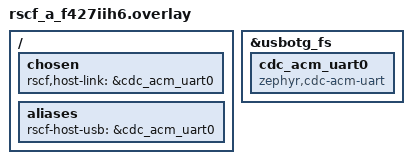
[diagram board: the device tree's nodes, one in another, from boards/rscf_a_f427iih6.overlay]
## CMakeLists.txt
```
cmake_minimum_required(VERSION 3.20.0)

list(APPEND BOARD_ROOT ${CMAKE_CURRENT_LIST_DIR}/..)
list(APPEND DTS_ROOT ${CMAKE_CURRENT_LIST_DIR}/..)
set(RSCF_SEGGER_MODULE_DIR ${CMAKE_CURRENT_LIST_DIR}/../modules/debug/segger)
set(RSCF_MICROROS_MODULE_DIR ${CMAKE_CURRENT_LIST_DIR}/../modules/lib/libmicroros)

if(EXISTS ${RSCF_SEGGER_MODULE_DIR}/zephyr/module.yml)
  list(APPEND ZEPHYR_EXTRA_MODULES ${RSCF_SEGGER_MODULE_DIR})
endif()

if(EXISTS ${RSCF_MICROROS_MODULE_DIR}/zephyr/module.yml)
  list(APPEND ZEPHYR_EXTRA_MODULES ${RSCF_MICROROS_MODULE_DIR})
endif()

find_package(Zephyr REQUIRED HINTS $ENV{ZEPHYR_BASE})
find_package(Python3 REQUIRED COMPONENTS Interpreter)
project(rscf_a_zephyr)
get_filename_component(RSCF_WEST_TOPDIR ${ZEPHYR_BASE} DIRECTORY)

set(RSCF_CMSIS_DSP_DIR ${CMAKE_CURRENT_LIST_DIR}/../third_party/cmsis_dsp)
set(RSCF_CMSIS_DSP_INCLUDE_DIR ${CMAKE_CURRENT_LIST_DIR}/../third_party/cmsis_dsp/Include)
set(RSCF_CMSIS_DSP_PRIVATE_INCLUDE_DIR ${CMAKE_CURRENT_LIST_DIR}/../third_party/cmsis_dsp/PrivateInclude)

set(RSCF_MCU_DEVICE "MCU_ONE" CACHE STRING "mcu_comm target MCU device")
set(RSCF_MCU_COMM_OUTPUT_DIR ${CMAKE_BINARY_DIR}/generated/mcu_comm/${RSCF_MCU_DEVICE})
set(RSCF_MCU_COMM_APP_DIR ${RSCF_MCU_COMM_OUTPUT_DIR}/app)
set(RSCF_MCU_COMM_CORE_DIR ${RSCF_MCU_COMM_OUTPUT_DIR}/core)
set(RSCF_MCU_COMM_TRANSPORT_DIR ${RSCF_MCU_COMM_OUTPUT_DIR}/transports)
set(RSCF_MCU_COMM_SYNC_DIR ${CMAKE_CURRENT_LIST_DIR}/../generated/mcu_comm)
file(GLOB RSCF_MCU_COMM_ZEPHYR_TEMPLATES
  ${CMAKE_CURRENT_LIST_DIR}/../mcu_comm/protocol_generator/templates/zephyr/*.j2
)

set(RSCF_MCU_COMM_GENERATED_HEADERS
  ${RSCF_MCU_COMM_APP_DIR}/data_def.h
  ${RSCF_MCU_COMM_APP_DIR}/robot_interface.h
  ${RSCF_MCU_COMM_CORE_DIR}/protocol.h
  ${RSCF_MCU_COMM_CORE_DIR}/comm_manager.h
  ${RSCF_MCU_COMM_TRANSPORT_DIR}/transport_interface.h
  ${RSCF_MCU_COMM_TRANSPORT_DIR}/transport_uart.h
  ${RSCF_MCU_COMM_TRANSPORT_DIR}/transport_can.h
  ${RSCF_MCU_COMM_TRANSPORT_DIR}/transport_usb.h
)

set(RSCF_MCU_COMM_GENERATED_SOURCES
  ${RSCF_MCU_COMM_APP_DIR}/data_def.c
  ${RSCF_MCU_COMM_APP_DIR}/robot_interface.c
  ${RSCF_MCU_COMM_CORE_DIR}/protocol.c
  ${RSCF_MCU_COMM_CORE_DIR}/comm_manager.c
  ${RSCF_MCU_COMM_TRANSPORT_DIR}/transport_uart.c
  ${RSCF_MCU_COMM_TRANSPORT_DIR}/transport_can.c
  ${RSCF_MCU_COMM_TRANSPORT_DIR}/transport_usb.c
)

add_custom_command(
  OUTPUT ${RSCF_MCU_COMM_GENERATED_HEADERS} ${RSCF_MCU_COMM_GENERATED_SOURCES}
  COMMAND ${Python3_EXECUTABLE}
          ${CMAKE_CURRENT_LIST_DIR}/../scripts/codegen/rscf_mcu_comm_codegen.py
          --device ${RSCF_MCU_DEVICE}
          --output-dir ${RSCF_MCU_COMM_OUTPUT_DIR}
  DEPENDS
          ${CMAKE_CURRENT_LIST_DIR}/../scripts/codegen/rscf_mcu_comm_codegen.py
          ${CMAKE_CURRENT_LIST_DIR}/../mcu_comm/protocol_generator/generator.py
          ${CMAKE_CURRENT_LIST_DIR}/../mcu_comm/protocol_generator/protocol_definition.json
          ${CMAKE_CURRENT_LIST_DIR}/../mcu_comm/protocol_generator/system_status_schema.yaml
          ${CMAKE_CURRENT_LIST_DIR}/../mcu_comm/protocol_generator/system_cmd_schema.yaml
          ${CMAKE_CURRENT_LIST_DIR}/../mcu_comm/protocol_generator/control_plane_enums.yaml
          ${RSCF_MCU_COMM_ZEPHYR_TEMPLATES}
  VERBATIM
)

add_custom_target(rscf_mcu_comm_codegen DEPENDS
  ${RSCF_MCU_COMM_GENERATED_HEADERS}
  ${RSCF_MCU_COMM_GENERATED_SOURCES}
)

add_custom_target(rscf_mcu_comm_sync
  COMMAND ${Python3_EXECUTABLE}
          ${CMAKE_CURRENT_LIST_DIR}/../scripts/codegen/rscf_mcu_comm_codegen.py
          --device ${RSCF_MCU_DEVICE}
          --output-dir ${RSCF_MCU_COMM_OUTPUT_DIR}
          --sync-dir ${RSCF_MCU_COMM_SYNC_DIR}
          --sync
  DEPENDS rscf_mcu_comm_codegen
  VERBATIM
)

add_custom_target(rscf_ioc_validate
  COMMAND ${Python3_EXECUTABLE}
          ${CMAKE_CURRENT_LIST_DIR}/../scripts/ioc/validate_board_from_ioc.py
          --repo-root ${CMAKE_CURRENT_LIST_DIR}/..
  VERBATIM
)

zephyr_include_directories(${ZEPHYR_BASE}/modules/cmsis_6)
zephyr_include_directories(${RSCF_WEST_TOPDIR}/third_party/hal/cmsis/CMSIS/Core/Include)
zephyr_compile_definitions(SHPR=SHP)
target_compile_definitions(app PRIVATE ARM_MATH_CM4 ARM_MATH_MATRIX_CHECK ARM_MATH_ROUNDING)

target_include_directories(app PRIVATE
  ${RSCF_CMSIS_DSP_INCLUDE_DIR}
  ${RSCF_CMSIS_DSP_PRIVATE_INCLUDE_DIR}
  ${CMAKE_CURRENT_LIST_DIR}/../include
  ${CMAKE_CURRENT_LIST_DIR}/../drivers/rscf
  ${CMAKE_CURRENT_LIST_DIR}/../drivers/bsp
  ${CMAKE_CURRENT_LIST_DIR}/../modules/rscf/services
  ${CMAKE_CURRENT_LIST_DIR}/../modules/rscf/devices
  ${RSCF_MCU_COMM_APP_DIR}
  ${RSCF_MCU_COMM_CORE_DIR}
  ${RSCF_MCU_COMM_TRANSPORT_DIR}
)

target_sources(app PRIVATE
  src/main.c
  ../drivers/bsp/bsp_usart.c
  ../drivers/bsp/bsp_log.c
  ../drivers/bsp/bsp_dwt.c
  ../drivers/bsp/bsp_can.c
  ../drivers/bsp/bsp_spi.c
  ../drivers/bsp/bsp_pwm.c
  ../drivers/bsp/bsp_tim.c
  ../drivers/rscf/rscf_boot.c
  ../drivers/rscf/rscf_led_status.c
  ../drivers/rscf/rscf_link_usb.c
  ../drivers/rscf/rscf_link_uart.c
  ../drivers/rscf/rscf_link_can.c
  ../drivers/rscf/rscf_link_spi.c
  ../drivers/rscf/rscf_ext_uart_mux.c
  ../drivers/rscf/rscf_buzzer.c
  ../drivers/rscf/rscf_power_switch.c
  ../modules/algorithm/coordinate_system.c
  ../modules/algorithm/crc8.c
  ../modules/algorithm/crc16.c
  ../modules/algorithm/linear_algebra.c
  ../modules/algorithm/Kalman_filter.c
  ../modules/algorithm/PID.c
  ../modules/algorithm/user_lib.c
  ../modules/compat/unit_convert.c
  ../modules/compat/controller.c
  ../modules/compat/daemon.c
  ../modules/compat/led.c
  ../modules/compat/buzzer.c
  ../modules/compat/hc05.c
  ../modules/compat/seasky_protocol.c
  ../modules/compat/master_process.c
  ../modules/compat/mhall.c
  ../modules/compat/ad7190.c
  ../modules/compat/oled.c
  ../modules/compat/remote_control.c
  ../modules/compat/robot.c
  ../modules/compat/robot_cmd.c
  ../modules/compat/motor_task.c
  ../third_party/cmsis_dsp/Source/CommonTables/arm_common_tables.c
  ../third_party/cmsis_dsp/Source/FastMathFunctions/arm_sin_f32.c
  ../third_party/cmsis_dsp/Source/FastMathFunctions/arm_cos_f32.c
  ../third_party/cmsis_dsp/Source/FastMathFunctions/arm_atan2_f32.c
  ../third_party/cmsis_dsp/Source/MatrixFunctions/arm_mat_init_f32.c
  ../third_party/cmsis_dsp/Source/MatrixFunctions/arm_mat_add_f32.c
  ../third_party/cmsis_dsp/Source/MatrixFunctions/arm_mat_sub_f32.c
  ../third_party/cmsis_dsp/Source/MatrixFunctions/arm_mat_mult_f32.c
  ../third_party/cmsis_dsp/Source/MatrixFunctions/arm_mat_trans_f32.c
  ../third_party/cmsis_dsp/Source/MatrixFunctions/arm_mat_inverse_f32.c
  ../modules/motor/dji_motor.c
  ../modules/motor/dmmotor.c
  ../modules/motor/servo_motor.c
  ../modules/rscf/core/rscf_app_profile.c
  ../modules/rscf/services/rscf_event_bus.c
  ../modules/rscf/services/rscf_link_service.c
  ../modules/rscf/services/rscf_service_router.c
  ../modules/rscf/services/rscf_action_service.c
  ../modules/rscf/services/rscf_daemon_service.c
  ../modules/rscf/services/rscf_health_service.c
  ../modules/rscf/services/rscf_comm_service.c
  ../modules/rscf/services/rscf_chassis_service.c
  ../modules/rscf/services/rscf_robot_service.c
  ../modules/rscf/services/rscf_ros_bridge.c
  ../modules/rscf/services/rscf_motor_service.c
  ../modules/rscf/services/rscf_debug_fault.c
  ../modules/rscf/devices/rscf_dtof2510.c
  ../modules/rscf/devices/rscf_imu_uart.c
  ../modules/rscf/devices/rscf_saber_imu_compat.c
  ${RSCF_MCU_COMM_GENERATED_SOURCES}
)

add_dependencies(app rscf_mcu_comm_codegen)
add_dependencies(app rscf_ioc_validate)

if(CONFIG_RSCF_MICROROS_SERVICE)
  target_sources(app PRIVATE
    ../modules/rscf/services/rscf_microros_service.c
  )
endif()
```

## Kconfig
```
mainmenu "RSCF A Zephyr Configuration"

source "Kconfig.zephyr"

menu "RSCF A Options"

rsource "../profiles/Kconfig"
rsource "../modules/rscf/Kconfig"

endmenu
```

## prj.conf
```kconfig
CONFIG_GPIO=y
CONFIG_SERIAL=y
CONFIG_CONSOLE=y
CONFIG_UART_CONSOLE=y
CONFIG_UART_INTERRUPT_DRIVEN=y
CONFIG_UART_LINE_CTRL=y
CONFIG_PINCTRL=y
CONFIG_LOG=y
CONFIG_LOG_MODE_IMMEDIATE=y
CONFIG_LOG_BACKEND_UART=n
CONFIG_LOG_BACKEND_RTT=y
CONFIG_LOG_BACKEND_RTT_MODE_DROP=y
CONFIG_LOG_BACKEND_RTT_MESSAGE_SIZE=256
CONFIG_USE_SEGGER_RTT=y
CONFIG_SEGGER_RTT_MAX_NUM_UP_BUFFERS=5
CONFIG_SEGGER_RTT_MAX_NUM_DOWN_BUFFERS=2
CONFIG_SEGGER_RTT_BUFFER_SIZE_UP=1024
CONFIG_SEGGER_RTT_BUFFER_SIZE_DOWN=64
CONFIG_RING_BUFFER=y
CONFIG_HEAP_MEM_POOL_SIZE=32768
CONFIG_MAIN_STACK_SIZE=24576
CONFIG_REBOOT=y
CONFIG_CAN=y
CONFIG_SPI=y
CONFIG_I2C=n
CONFIG_PWM=y
CONFIG_SENSOR=y
CONFIG_ASSERT=y
CONFIG_CPP=y
CONFIG_NEWLIB_LIBC=y
CONFIG_NEWLIB_LIBC_NANO=n
CONFIG_POSIX_API=y
CONFIG_USB_DEVICE_STACK=y
CONFIG_USB_DEVICE_STACK_NEXT=n
CONFIG_USB_CDC_ACM=y
CONFIG_USB_DEVICE_INITIALIZE_AT_BOOT=n
CONFIG_USB_DEVICE_PRODUCT="RSCF A CDC ACM"
CONFIG_USB_DEVICE_PID=0x2026

CONFIG_RSCF_PROFILE_MINIMAL_BRINGUP=y
CONFIG_RSCF_EVENT_BUS=y
CONFIG_RSCF_DAEMON_SERVICE=y
CONFIG_RSCF_HEALTH_SERVICE=y
CONFIG_RSCF_LINK_VNEXT=y
CONFIG_RSCF_LINK_HOST_USB=y
CONFIG_RSCF_LINK_PEER_UART=y
CONFIG_RSCF_LINK_COMPAT_SYSTEM_CMD=y
CONFIG_RSCF_ROS_BACKEND_BRIDGE=y
CONFIG_RSCF_ROS_BACKEND_MICROROS=n
CONFIG_RSCF_COMM_SERVICE=y
CONFIG_RSCF_CHASSIS_SERVICE=y
CONFIG_RSCF_MOTOR_SERVICE=y
```

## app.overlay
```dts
&usbotg_fs {
	cdc_acm_uart0: cdc_acm_uart0 {
		compatible = "zephyr,cdc-acm-uart";
	};
};
```

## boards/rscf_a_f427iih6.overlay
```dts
/ {
	chosen {
		rscf,host-link = &cdc_acm_uart0;
	};

	aliases {
		rscf-host-usb = &cdc_acm_uart0;
	};
};

&usbotg_fs {
	cdc_acm_uart0: cdc_acm_uart0 {
		compatible = "zephyr,cdc-acm-uart";
	};
};
```

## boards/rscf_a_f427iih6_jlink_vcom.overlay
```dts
&rscf_board {
	comm-uart = <&usart1>;
};
```

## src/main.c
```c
#include <zephyr/kernel.h>
#include <zephyr/logging/log.h>

#include <rscf/rscf_app_profile.h>
#include <rscf/rscf_boot.h>

LOG_MODULE_REGISTER(rscf_main, LOG_LEVEL_INF);

#define RSCF_MAIN_LOOP_PERIOD_MS 1

int main(void)
{
  int ret;

  LOG_INF("RSCF A Zephyr bring-up start");

  ret = RSCFBootRun();
  if (ret != 0) {
    LOG_ERR("boot failed: %d", ret);
    return ret;
  }

  ret = RSCFAppProfileInit();
  if (ret != 0) {
    LOG_ERR("profile init failed: %d", ret);
    return ret;
  }

  LOG_INF("active profile: %s", RSCFAppProfileName());

  while (1) {
    RSCFAppProfileTick();
    k_sleep(K_MSEC(RSCF_MAIN_LOOP_PERIOD_MS));
  }
}
```
